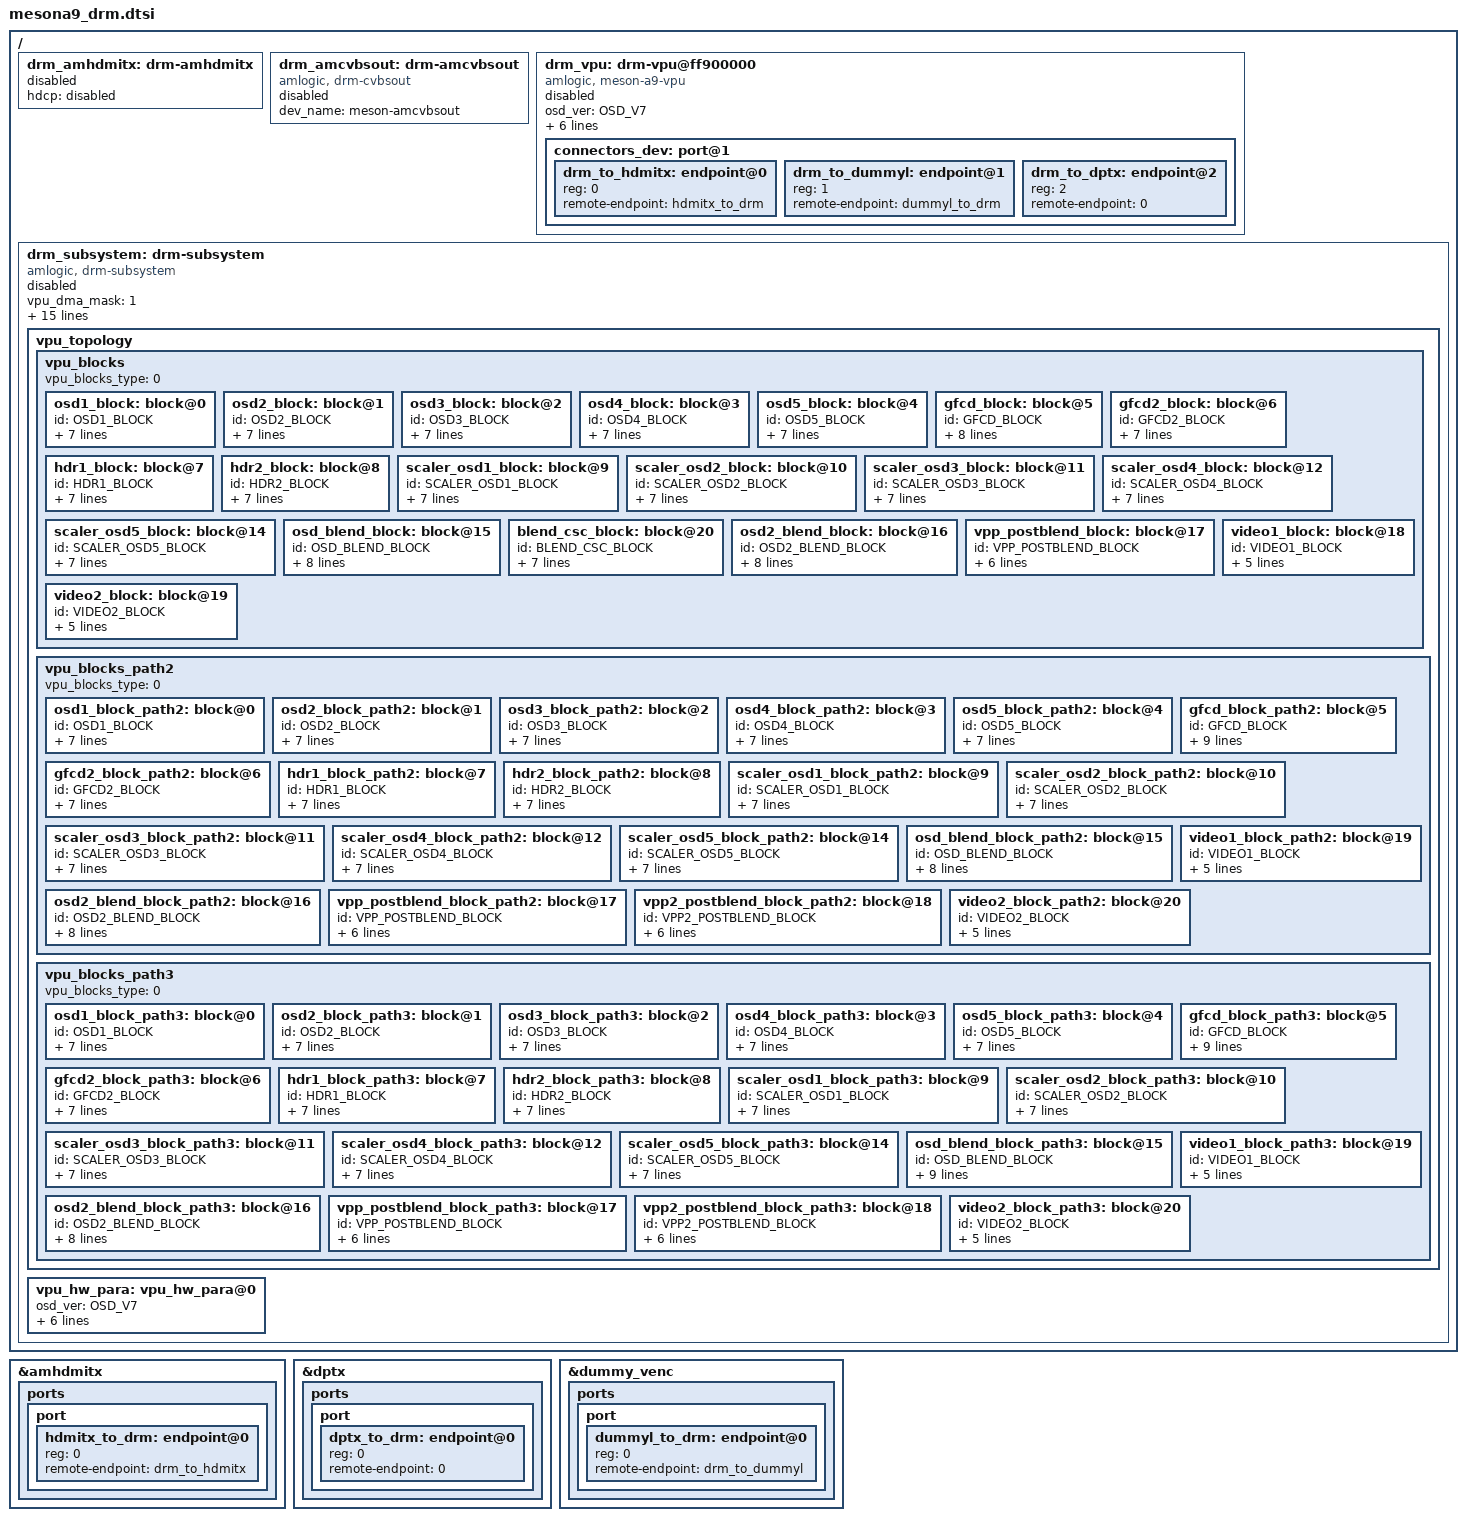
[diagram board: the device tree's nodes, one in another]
// SPDX-License-Identifier: (GPL-2.0+ OR MIT)
/*
 * Copyright (c) 2019 Amlogic, Inc. All rights reserved.
 */

#include <dt-bindings/display/meson-drm-ids.h>
#include "meson-a9.dtsi"

/ {
	drm_amhdmitx: drm-amhdmitx {
		status = "disabled";
		hdcp = "disabled";
	};

	drm_amcvbsout: drm-amcvbsout {
		status = "disabled";
		compatible = "amlogic, drm-cvbsout";
		dev_name = "meson-amcvbsout";
		//ports {
		//	port {
		//		#address-cells = <1>;
		//		#size-cells = <0>;
		//	};
		//};
	};

	drm_vpu: drm-vpu@ff900000  {
		status = "disabled";
		//compatible = "amlogic, meson-s6-vpu";
		compatible = "amlogic, meson-a9-vpu";
		osd_ver = /bits/ 8 <OSD_V7>;
		reg = <0x0 0xff900000 0x0 0x40000>,
			  <0x0 0xff63c000 0x0 0x2000>,
			  <0x0 0xff638000 0x0 0x2000>;
		reg-names = "base", "hhi", "dmc";
		interrupts = <GIC_SPI 197 IRQ_TYPE_EDGE_RISING>,
				<GIC_SPI 194 IRQ_TYPE_EDGE_RISING>;
		interrupt-names = "viu-vsync", "viu2-vsync";
		dma-coherent;
		//clocks = <&clkc CLKID_VPU_CLKC>;
		//clock-names = "vpu_clkc";
		//assigned-clocks = <&clkc CLKID_VPU_CLKC>;
		//assigned-clock-rates = <200000000>;
		/*EXTERNAL port for driver outside of drm.*/
		connectors_dev: port@1 {
			#address-cells = <1>;
			#size-cells = <0>;
			drm_to_hdmitx: endpoint@0 {
				reg = <0>;
				remote-endpoint = <&hdmitx_to_drm>;
			};
			drm_to_dummyl: endpoint@1 {
				reg = <1>;
				remote-endpoint = <&dummyl_to_drm>;
			};
			drm_to_dptx: endpoint@2 {
				reg = <2>;
				remote-endpoint = <0>;
			};
			//drm_to_edp: endpoint@2 {
			//	reg = <1>;
			//	remote-endpoint = <&edp_to_drm>;
			//};
			//drm_to_dummyl: endpoint@1 {
			//	reg = <1>;
			//	remote-endpoint = <0>;
			//};
		};
	};

	drm_subsystem: drm-subsystem {
		status = "disabled";
		compatible = "amlogic, drm-subsystem";
		vpu_dma_mask = <1>; /* 0: <= 4G, 1: > 4G */
		ports = <&connectors_dev>;
		fbdev_sizes = <1920 1080 1920 2160 32>;
		max_fb_size = <1>; /** 0:1080p fb 1:4k fb */
		memory-region = <&logo_reserved>;
		primary_plane_index = <0>; /* primary plane index for crtcs */
		crtc_masks = <1 0 0>; /*for encoder: 0:hdmi 1:lcd 2:cvbs*/
		crtcmask_of_osd = <0 0 0 0 0>; /* indicate the crtc mask of osd plane */
		crtcmask_of_video = <0 1 0>; /* indicate the crtc mask of video plane */
		gamma_ctl = <0>; /*0:skip gamma init 1:gamma init*/
		pxp_mode = <0>;
		osd_afbc_mask = <7>;
		gfcd_enable = /bits/ 8  <1>;
		afbc_aligned_size = <1>; /*0:fbdev alloc non-afbc memory 1:fbdev alloc afbc memory*/
		vpu_block_select = <&vpu_blocks>; /*default vpu_blocks*/
		//vpu_block_select = <&vpu_blocks_path2>;
		//vpu_block_select = <&vpu_blocks_path3>;
		tx_venc = <&tx_venc>;

		vpu_topology: vpu_topology {
			vpu_blocks: vpu_blocks {
				/*0:scaler before osdblend, 1:hdr before osdblend*/
				vpu_blocks_type = <0>;
				osd1_block: block@0 {
					id = /bits/ 8 <OSD1_BLOCK>;
					index = /bits/ 8  <0>;
					type = /bits/ 8  <0>;
					block_name = "osd1_block";
					num_in_links = /bits/ 8  <0x0>;
					num_out_links = /bits/ 8  <0x1>;
					out_links = <0 &gfcd_block>;
					capability = /bits/ 64 <0x80000C9F>;
				};
				osd2_block: block@1 {
					id = /bits/ 8  <OSD2_BLOCK>;
					index = /bits/ 8  <1>;
					type = /bits/ 8  <0>;
					block_name = "osd2_block";
					num_in_links = /bits/ 8  <0x0>;
					num_out_links = /bits/ 8  <0x1>;
					out_links = <1 &gfcd_block>;
					capability = /bits/ 64 <0x80000C9F>;
				};
				osd3_block: block@2 {
					id = /bits/ 8  <OSD3_BLOCK>;
					index = /bits/ 8  <2>;
					type = /bits/ 8  <0>;
					block_name = "osd3_block";
					num_in_links = /bits/ 8  <0x0>;
					num_out_links = /bits/ 8  <0x1>;
					out_links = <0 &gfcd2_block>;
					capability = /bits/ 64 <0x80000C0F>;
				};
				osd4_block: block@3 {
					id = /bits/ 8  <OSD4_BLOCK>;
					index = /bits/ 8  <3>;
					type = /bits/ 8  <0>;
					block_name = "osd4_block";
					num_in_links = /bits/ 8  <0x0>;
					num_out_links = /bits/ 8  <0x1>;
					out_links = <0 &scaler_osd4_block>;
					capability = /bits/ 64 <0x80000C8E>;
				};
				osd5_block: block@4 {
					id = /bits/ 8  <OSD5_BLOCK>;
					index = /bits/ 8  <4>;
					type = /bits/ 8  <0>;
					block_name = "osd5_block";
					num_in_links = /bits/ 8  <0x0>;
					num_out_links = /bits/ 8  <0x1>;
					out_links = <0 &scaler_osd5_block>;
					capability = /bits/ 64 <0x80000C0E>;
				};
				gfcd_block: block@5 {
					id = /bits/ 8  <GFCD_BLOCK>;
					index = /bits/ 8  <0>;
					type = /bits/ 8  <9>;
					block_name = "gfcd_block";
					num_in_links = /bits/ 8  <0x2>;
					in_links = <0 &osd1_block>,
						<0 &osd2_block>;
					num_out_links = /bits/ 8  <0x2>;
					out_links = <0 &scaler_osd1_block>,
						<0 &scaler_osd2_block>;
				};
				gfcd2_block: block@6 {
					id = /bits/ 8  <GFCD2_BLOCK>;
					index = /bits/ 8  <1>;
					type = /bits/ 8  <9>;
					block_name = "gfcd2_block";
					num_in_links = /bits/ 8  <0x1>;
					in_links = <0 &osd3_block>;
					num_out_links = /bits/ 8  <0x1>;
					out_links = <0 &scaler_osd3_block>;
				};

				hdr1_block: block@7 {
					id = /bits/ 8  <HDR1_BLOCK>;
					index = /bits/ 8  <0>;
					block_name = "hdr1_block";
					type = /bits/ 8  <4>;
					num_in_links = /bits/ 8  <0x1>;
					in_links = <0 &scaler_osd1_block>;
					num_out_links = /bits/ 8  <0x1>;
					out_links = <0 &osd_blend_block>;
				};
				hdr2_block: block@8 {
					id = /bits/ 8  <HDR2_BLOCK>;
					index = /bits/ 8  <1>;
					block_name = "hdr2_block";
					type = /bits/ 8  <4>;
					num_in_links = /bits/ 8  <0x1>;
					in_links = <0 &scaler_osd2_block>;
					num_out_links = /bits/ 8  <0x1>;
					out_links = <1 &osd_blend_block>;
				};
				scaler_osd1_block: block@9 {
					id = /bits/ 8  <SCALER_OSD1_BLOCK>;
					index = /bits/ 8  <0>;
					type = /bits/ 8  <2>;
					block_name = "scaler_osd1_block";
					num_in_links = /bits/ 8  <0x1>;
					in_links = <0 &gfcd_block>;
					num_out_links = /bits/ 8  <0x1>;
					out_links = <0 &hdr1_block>;
				};
				scaler_osd2_block: block@10 {
					id = /bits/ 8  <SCALER_OSD2_BLOCK>;
					index = /bits/ 8  <1>;
					type = /bits/ 8  <2>;
					block_name = "scaler_osd2_block";
					num_in_links = /bits/ 8  <0x1>;
					in_links = <1 &gfcd_block>;
					num_out_links = /bits/ 8  <0x1>;
					out_links = <0 &hdr2_block>;
				};
				scaler_osd3_block: block@11 {
					id = /bits/ 8  <SCALER_OSD3_BLOCK>;
					index = /bits/ 8  <2>;
					type = /bits/ 8  <2>;
					block_name = "scaler_osd3_block";
					num_in_links = /bits/ 8  <0x1>;
					in_links = <0 &gfcd2_block>;
					num_out_links = /bits/ 8  <0x1>;
					out_links = <2 &osd_blend_block>;
				};
				scaler_osd4_block: block@12 {
					id = /bits/ 8  <SCALER_OSD4_BLOCK>;
					index = /bits/ 8  <3>;
					type = /bits/ 8  <2>;
					block_name = "scaler_osd4_block";
					num_in_links = /bits/ 8  <0x1>;
					in_links = <0 &osd4_block>;
					num_out_links = /bits/ 8  <0x1>;
					out_links = <0 &osd2_blend_block>;
				};
				scaler_osd5_block: block@14 {
					id = /bits/ 8  <SCALER_OSD5_BLOCK>;
					index = /bits/ 8  <4>;
					type = /bits/ 8  <2>;
					block_name = "scaler_osd5_block";
					num_in_links = /bits/ 8  <0x1>;
					in_links = <0 &osd5_block>;
					num_out_links = /bits/ 8  <0x1>;
					out_links = <1 &osd2_blend_block>;
				};
				osd_blend_block: block@15 {
					id = /bits/ 8  <OSD_BLEND_BLOCK>;
					index = /bits/ 8  <0>;
					block_name = "osd_blend_block";
					type = /bits/ 8  <3>;
					num_in_links = /bits/ 8  <0x4>;
					in_links = <0 &hdr1_block>,
						<0 &hdr2_block>,
						<0 &scaler_osd3_block>,
						<0 &osd2_blend_block>;
					num_out_links = /bits/ 8  <0x1>;
					out_links = <0 &blend_csc_block>;
				};
				blend_csc_block: block@20 {
					id = /bits/ 8  <BLEND_CSC_BLOCK>;
					index = /bits/ 8  <0>;
					block_name = "blend_csc_block";
					type = /bits/ 8  <10>;
					num_in_links = /bits/ 8  <0x1>;
					in_links = <0 &osd_blend_block>;
					num_out_links = /bits/ 8  <0x1>;
					out_links = <0 &vpp_postblend_block>;
				};
				osd2_blend_block: block@16 {
					id = /bits/ 8  <OSD2_BLEND_BLOCK>;
					index = /bits/ 8  <1>;
					block_name = "osd2_blend_block";
					type = /bits/ 8  <3>;
					num_in_links = /bits/ 8  <0x2>;
					in_links = <0 &scaler_osd4_block>,
						<0 &scaler_osd5_block>;
					num_out_links = /bits/ 8  <0x1>;
					out_links = <3 &osd_blend_block>;
				};
				vpp_postblend_block: block@17 {
					id = /bits/ 8  <VPP_POSTBLEND_BLOCK>;
					index = /bits/ 8  <0>;
					block_name = "vpp_postblend_block";
					type = /bits/ 8  <6>;
					num_in_links = /bits/ 8  <0x1>;
					in_links = <0 &blend_csc_block>;
					num_out_links = <0x0>;
				};
				//vpp2_postblend_block: block@18 {
				//	id = /bits/ 8  <VPP2_POSTBLEND_BLOCK>;
				//	index = /bits/ 8  <1>;
				//	block_name = "vpp2_postblend_block";
				//	type = /bits/ 8  <6>;
				//	num_in_links = /bits/ 8  <0x0>;
					//in_links = <0x0>;
					//num_out_links = <0x0>;
				//};
				video1_block: block@18 {
					id = /bits/ 8 <VIDEO1_BLOCK>;
					index = /bits/ 8  <0>;
					type = /bits/ 8  <7>;
					block_name = "video1_block";
					num_in_links = /bits/ 8  <0x0>;
					num_out_links = /bits/ 8  <0x0>;
				};
				video2_block: block@19 {
					id = /bits/ 8 <VIDEO2_BLOCK>;
					index = /bits/ 8  <1>;
					type = /bits/ 8  <7>;
					block_name = "video2_block";
					num_in_links = /bits/ 8  <0x0>;
					num_out_links = /bits/ 8  <0x0>;
				};
			};

			vpu_blocks_path2: vpu_blocks_path2 {
				/*osd3->vpp2*/
				vpu_blocks_type = <0>;
				osd1_block_path2: block@0 {
					id = /bits/ 8 <OSD1_BLOCK>;
					index = /bits/ 8  <0>;
					type = /bits/ 8  <0>;
					block_name = "osd1_block";
					num_in_links = /bits/ 8  <0x0>;
					num_out_links = /bits/ 8  <0x1>;
					out_links = <0 &gfcd_block_path2>;
					capability = /bits/ 64 <0x80000C9F>;
				};
				osd2_block_path2: block@1 {
					id = /bits/ 8  <OSD2_BLOCK>;
					index = /bits/ 8  <1>;
					type = /bits/ 8  <0>;
					block_name = "osd2_block";
					num_in_links = /bits/ 8  <0x0>;
					num_out_links = /bits/ 8  <0x1>;
					out_links = <1 &gfcd_block_path2>;
					capability = /bits/ 64 <0x80000C9F>;
				};
				osd3_block_path2: block@2 {
					id = /bits/ 8  <OSD3_BLOCK>;
					index = /bits/ 8  <2>;
					type = /bits/ 8  <0>;
					block_name = "osd3_block";
					num_in_links = /bits/ 8  <0x0>;
					num_out_links = /bits/ 8  <0x1>;
					out_links = <0 &gfcd2_block_path2>;
					capability = /bits/ 64 <0x8000040F>;
				};
				osd4_block_path2: block@3 {
					id = /bits/ 8  <OSD4_BLOCK>;
					index = /bits/ 8  <3>;
					type = /bits/ 8  <0>;
					block_name = "osd4_block";
					num_in_links = /bits/ 8  <0x0>;
					num_out_links = /bits/ 8  <0x1>;
					out_links = <0 &scaler_osd4_block_path2>;
					capability = /bits/ 64 <0x80000C8E>;
				};
				osd5_block_path2: block@4 {
					id = /bits/ 8  <OSD5_BLOCK>;
					index = /bits/ 8  <4>;
					type = /bits/ 8  <0>;
					block_name = "osd5_block";
					num_in_links = /bits/ 8  <0x0>;
					num_out_links = /bits/ 8  <0x1>;
					out_links = <0 &scaler_osd5_block_path2>;
					capability = /bits/ 64 <0x80000C0E>;
				};
				gfcd_block_path2: block@5 {
					id = /bits/ 8  <GFCD_BLOCK>;
					index = /bits/ 8  <0>;
					type = /bits/ 8  <9>;
					block_name = "gfcd_block";
					num_in_links = /bits/ 8  <0x2>;
					in_links = <0 &osd1_block_path2>,
						<0 &osd2_block_path2>;
					num_out_links = /bits/ 8  <0x2>;
					out_links = <0 &scaler_osd1_block_path2>,
						<0 &scaler_osd2_block_path2>;
				};
				gfcd2_block_path2: block@6 {
					id = /bits/ 8  <GFCD2_BLOCK>;
					index = /bits/ 8  <1>;
					type = /bits/ 8  <9>;
					block_name = "gfcd2_block";
					num_in_links = /bits/ 8  <0x1>;
					in_links = <0 &osd3_block_path2>;
					num_out_links = /bits/ 8  <0x1>;
					out_links = <0 &scaler_osd3_block_path2>;
				};

				hdr1_block_path2: block@7 {
					id = /bits/ 8  <HDR1_BLOCK>;
					index = /bits/ 8  <0>;
					block_name = "hdr1_block";
					type = /bits/ 8  <4>;
					num_in_links = /bits/ 8  <0x1>;
					in_links = <0 &scaler_osd1_block_path2>;
					num_out_links = /bits/ 8  <0x1>;
					out_links = <0 &osd_blend_block_path2>;
				};
				hdr2_block_path2: block@8 {
					id = /bits/ 8  <HDR2_BLOCK>;
					index = /bits/ 8  <1>;
					block_name = "hdr2_block";
					type = /bits/ 8  <4>;
					num_in_links = /bits/ 8  <0x1>;
					in_links = <0 &scaler_osd2_block_path2>;
					num_out_links = /bits/ 8  <0x1>;
					out_links = <1 &osd_blend_block_path2>;
				};
				scaler_osd1_block_path2: block@9 {
					id = /bits/ 8  <SCALER_OSD1_BLOCK>;
					index = /bits/ 8  <0>;
					type = /bits/ 8  <2>;
					block_name = "scaler_osd1_block";
					num_in_links = /bits/ 8  <0x1>;
					in_links = <0 &gfcd_block_path2>;
					num_out_links = /bits/ 8  <0x1>;
					out_links = <0 &hdr1_block_path2>;
				};
				scaler_osd2_block_path2: block@10 {
					id = /bits/ 8  <SCALER_OSD2_BLOCK>;
					index = /bits/ 8  <1>;
					type = /bits/ 8  <2>;
					block_name = "scaler_osd2_block";
					num_in_links = /bits/ 8  <0x1>;
					in_links = <1 &gfcd_block_path2>;
					num_out_links = /bits/ 8  <0x1>;
					out_links = <0 &hdr2_block_path2>;
				};
				scaler_osd3_block_path2: block@11 {
					id = /bits/ 8  <SCALER_OSD3_BLOCK>;
					index = /bits/ 8  <2>;
					type = /bits/ 8  <2>;
					block_name = "scaler_osd3_block";
					num_in_links = /bits/ 8  <0x1>;
					in_links = <0 &gfcd2_block_path2>;
					num_out_links = /bits/ 8  <0x1>;
					out_links = <0 &vpp2_postblend_block_path2>;
				};
				scaler_osd4_block_path2: block@12 {
					id = /bits/ 8  <SCALER_OSD4_BLOCK>;
					index = /bits/ 8  <3>;
					type = /bits/ 8  <2>;
					block_name = "scaler_osd4_block";
					num_in_links = /bits/ 8  <0x1>;
					in_links = <0 &osd4_block_path2>;
					num_out_links = /bits/ 8  <0x1>;
					out_links = <0 &osd2_blend_block_path2>;
				};
				scaler_osd5_block_path2: block@14 {
					id = /bits/ 8  <SCALER_OSD5_BLOCK>;
					index = /bits/ 8  <4>;
					type = /bits/ 8  <2>;
					block_name = "scaler_osd5_block";
					num_in_links = /bits/ 8  <0x1>;
					in_links = <0 &osd5_block_path2>;
					num_out_links = /bits/ 8  <0x1>;
					out_links = <1 &osd2_blend_block_path2>;
				};
				osd_blend_block_path2: block@15 {
					id = /bits/ 8  <OSD_BLEND_BLOCK>;
					index = /bits/ 8  <0>;
					block_name = "osd_blend_block";
					type = /bits/ 8  <3>;
					num_in_links = /bits/ 8  <0x3>;
					in_links = <0 &hdr1_block_path2>,
						<0 &hdr2_block_path2>,
						<0 &osd2_blend_block_path2>;
					num_out_links = /bits/ 8  <0x1>;
					out_links = <0 &vpp_postblend_block_path2>;
				};
				osd2_blend_block_path2: block@16 {
					id = /bits/ 8  <OSD2_BLEND_BLOCK>;
					index = /bits/ 8  <1>;
					block_name = "osd2_blend_block";
					type = /bits/ 8  <3>;
					num_in_links = /bits/ 8  <0x2>;
					in_links = <0 &scaler_osd4_block_path2>,
						<0 &scaler_osd5_block_path2>;
					num_out_links = /bits/ 8  <0x1>;
					out_links = <2 &osd_blend_block_path2>;
				};
				vpp_postblend_block_path2: block@17 {
					id = /bits/ 8  <VPP_POSTBLEND_BLOCK>;
					index = /bits/ 8  <0>;
					block_name = "vpp_postblend_block";
					type = /bits/ 8  <6>;
					num_in_links = /bits/ 8  <0x1>;
					in_links = <0 &osd_blend_block_path2>;
					num_out_links = <0x0>;
				};
				vpp2_postblend_block_path2: block@18 {
					id = /bits/ 8  <VPP2_POSTBLEND_BLOCK>;
					index = /bits/ 8  <1>;
					block_name = "vpp2_postblend_block";
					type = /bits/ 8  <6>;
					num_in_links = /bits/ 8  <0x1>;
					in_links = <0 &scaler_osd3_block_path2>;
					num_out_links = <0x0>;
				};
				video1_block_path2: block@19 {
					id = /bits/ 8 <VIDEO1_BLOCK>;
					index = /bits/ 8  <0>;
					type = /bits/ 8  <7>;
					block_name = "video1_block";
					num_in_links = /bits/ 8  <0x0>;
					num_out_links = /bits/ 8  <0x0>;
				};
				video2_block_path2: block@20 {
					id = /bits/ 8 <VIDEO2_BLOCK>;
					index = /bits/ 8  <1>;
					type = /bits/ 8  <7>;
					block_name = "video2_block";
					num_in_links = /bits/ 8  <0x0>;
					num_out_links = /bits/ 8  <0x0>;
				};
			};

			vpu_blocks_path3: vpu_blocks_path3 {
				/*osd2 -> vpp2*/
				vpu_blocks_type = <0>;
				osd1_block_path3: block@0 {
					id = /bits/ 8 <OSD1_BLOCK>;
					index = /bits/ 8  <0>;
					type = /bits/ 8  <0>;
					block_name = "osd1_block";
					num_in_links = /bits/ 8  <0x0>;
					num_out_links = /bits/ 8  <0x1>;
					out_links = <0 &gfcd_block_path3>;
					capability = /bits/ 64 <0x80000C9F>;
				};
				osd2_block_path3: block@1 {
					id = /bits/ 8  <OSD2_BLOCK>;
					index = /bits/ 8  <1>;
					type = /bits/ 8  <0>;
					block_name = "osd2_block";
					num_in_links = /bits/ 8  <0x0>;
					num_out_links = /bits/ 8  <0x1>;
					out_links = <1 &gfcd_block_path3>;
					capability = /bits/ 64 <0x8000049F>;
				};
				osd3_block_path3: block@2 {
					id = /bits/ 8  <OSD3_BLOCK>;
					index = /bits/ 8  <2>;
					type = /bits/ 8  <0>;
					block_name = "osd3_block";
					num_in_links = /bits/ 8  <0x0>;
					num_out_links = /bits/ 8  <0x1>;
					out_links = <0 &gfcd2_block_path3>;
					capability = /bits/ 64 <0x80000C0F>;
				};
				osd4_block_path3: block@3 {
					id = /bits/ 8  <OSD4_BLOCK>;
					index = /bits/ 8  <3>;
					type = /bits/ 8  <0>;
					block_name = "osd4_block";
					num_in_links = /bits/ 8  <0x0>;
					num_out_links = /bits/ 8  <0x1>;
					out_links = <0 &scaler_osd4_block_path3>;
					capability = /bits/ 64 <0x80000C8E>;
				};
				osd5_block_path3: block@4 {
					id = /bits/ 8  <OSD5_BLOCK>;
					index = /bits/ 8  <4>;
					type = /bits/ 8  <0>;
					block_name = "osd5_block";
					num_in_links = /bits/ 8  <0x0>;
					num_out_links = /bits/ 8  <0x1>;
					out_links = <0 &scaler_osd5_block_path3>;
					capability = /bits/ 64 <0x80000C0E>;
				};
				gfcd_block_path3: block@5 {
					id = /bits/ 8  <GFCD_BLOCK>;
					index = /bits/ 8  <0>;
					type = /bits/ 8  <9>;
					block_name = "gfcd_block";
					num_in_links = /bits/ 8  <0x2>;
					in_links = <0 &osd1_block_path3>,
						<0 &osd2_block_path3>;
					num_out_links = /bits/ 8  <0x2>;
					out_links = <0 &scaler_osd1_block_path3>,
						<0 &scaler_osd2_block_path3>;
				};
				gfcd2_block_path3: block@6 {
					id = /bits/ 8  <GFCD2_BLOCK>;
					index = /bits/ 8  <1>;
					type = /bits/ 8  <9>;
					block_name = "gfcd2_block";
					num_in_links = /bits/ 8  <0x1>;
					in_links = <0 &osd3_block_path3>;
					num_out_links = /bits/ 8  <0x1>;
					out_links = <0 &scaler_osd3_block_path3>;
				};

				hdr1_block_path3: block@7 {
					id = /bits/ 8  <HDR1_BLOCK>;
					index = /bits/ 8  <0>;
					block_name = "hdr1_block";
					type = /bits/ 8  <4>;
					num_in_links = /bits/ 8  <0x1>;
					in_links = <0 &scaler_osd1_block_path3>;
					num_out_links = /bits/ 8  <0x1>;
					out_links = <0 &osd_blend_block_path3>;
				};
				hdr2_block_path3: block@8 {
					id = /bits/ 8  <HDR2_BLOCK>;
					index = /bits/ 8  <1>;
					block_name = "hdr2_block";
					type = /bits/ 8  <4>;
					num_in_links = /bits/ 8  <0x1>;
					in_links = <0 &scaler_osd2_block_path3>;
					num_out_links = /bits/ 8  <0x1>;
					out_links = <0 &vpp2_postblend_block_path3>;
				};
				scaler_osd1_block_path3: block@9 {
					id = /bits/ 8  <SCALER_OSD1_BLOCK>;
					index = /bits/ 8  <0>;
					type = /bits/ 8  <2>;
					block_name = "scaler_osd1_block";
					num_in_links = /bits/ 8  <0x1>;
					in_links = <0 &gfcd_block_path3>;
					num_out_links = /bits/ 8  <0x1>;
					out_links = <0 &hdr1_block_path3>;
				};
				scaler_osd2_block_path3: block@10 {
					id = /bits/ 8  <SCALER_OSD2_BLOCK>;
					index = /bits/ 8  <1>;
					type = /bits/ 8  <2>;
					block_name = "scaler_osd2_block";
					num_in_links = /bits/ 8  <0x1>;
					in_links = <1 &gfcd_block_path3>;
					num_out_links = /bits/ 8  <0x1>;
					out_links = <0 &hdr2_block_path3>;
				};
				scaler_osd3_block_path3: block@11 {
					id = /bits/ 8  <SCALER_OSD3_BLOCK>;
					index = /bits/ 8  <2>;
					type = /bits/ 8  <2>;
					block_name = "scaler_osd3_block";
					num_in_links = /bits/ 8  <0x1>;
					in_links = <0 &gfcd2_block_path3>;
					num_out_links = /bits/ 8  <0x1>;
					out_links = <1 &osd_blend_block_path3>;
				};
				scaler_osd4_block_path3: block@12 {
					id = /bits/ 8  <SCALER_OSD4_BLOCK>;
					index = /bits/ 8  <3>;
					type = /bits/ 8  <2>;
					block_name = "scaler_osd4_block";
					num_in_links = /bits/ 8  <0x1>;
					in_links = <0 &osd4_block_path3>;
					num_out_links = /bits/ 8  <0x1>;
					out_links = <0 &osd2_blend_block_path3>;
				};
				scaler_osd5_block_path3: block@14 {
					id = /bits/ 8  <SCALER_OSD5_BLOCK>;
					index = /bits/ 8  <4>;
					type = /bits/ 8  <2>;
					block_name = "scaler_osd5_block";
					num_in_links = /bits/ 8  <0x1>;
					in_links = <0 &osd5_block_path3>;
					num_out_links = /bits/ 8  <0x1>;
					out_links = <1 &osd2_blend_block_path3>;
				};
				osd_blend_block_path3: block@15 {
					id = /bits/ 8  <OSD_BLEND_BLOCK>;
					index = /bits/ 8  <0>;
					block_name = "osd_blend_block";
					type = /bits/ 8  <3>;
					num_in_links = /bits/ 8  <0x3>;
					in_links = <0 &hdr1_block_path3>,
						<0 &scaler_osd3_block_path3>,
						<0 &osd2_blend_block_path3>;
					num_out_links = /bits/ 8  <0x1>;
					out_links = <0 &vpp_postblend_block_path3>;
				};
				osd2_blend_block_path3: block@16 {
					id = /bits/ 8  <OSD2_BLEND_BLOCK>;
					index = /bits/ 8  <1>;
					block_name = "osd2_blend_block";
					type = /bits/ 8  <3>;
					num_in_links = /bits/ 8  <0x2>;
					in_links = <0 &scaler_osd4_block_path3>,
						<0 &scaler_osd5_block_path3>;
					num_out_links = /bits/ 8  <0x1>;
					out_links = <2 &osd_blend_block_path3>;
				};
				vpp_postblend_block_path3: block@17 {
					id = /bits/ 8  <VPP_POSTBLEND_BLOCK>;
					index = /bits/ 8  <0>;
					block_name = "vpp_postblend_block";
					type = /bits/ 8  <6>;
					num_in_links = /bits/ 8  <0x1>;
					in_links = <0 &osd_blend_block_path3>;
					num_out_links = <0x0>;
				};
				vpp2_postblend_block_path3: block@18 {
					id = /bits/ 8  <VPP2_POSTBLEND_BLOCK>;
					index = /bits/ 8  <1>;
					block_name = "vpp2_postblend_block";
					type = /bits/ 8  <6>;
					num_in_links = /bits/ 8  <0x1>;
					in_links = <0 &hdr2_block_path3>;
					num_out_links = <0x0>;
				};
				video1_block_path3: block@19 {
					id = /bits/ 8 <VIDEO1_BLOCK>;
					index = /bits/ 8  <0>;
					type = /bits/ 8  <7>;
					block_name = "video1_block";
					num_in_links = /bits/ 8  <0x0>;
					num_out_links = /bits/ 8  <0x0>;
				};
				video2_block_path3: block@20 {
					id = /bits/ 8 <VIDEO2_BLOCK>;
					index = /bits/ 8  <1>;
					type = /bits/ 8  <7>;
					block_name = "video2_block";
					num_in_links = /bits/ 8  <0x0>;
					num_out_links = /bits/ 8  <0x0>;
				};
			};
		};
		vpu_hw_para: vpu_hw_para@0 {
			osd_ver = /bits/ 8 <OSD_V7>;
			afbc_type = /bits/ 8 <0x2>;
			has_deband = /bits/ 8 <0x1>;
			has_lut = /bits/ 8 <0x1>;
			has_rdma = /bits/ 8 <0x1>;
			osd_fifo_len = /bits/ 8 <64>;
			vpp_fifo_len = /bits/ 32 <0xfff>;
		};
	};
};

&amhdmitx {
	ports {
		port {
			#address-cells = <1>;
			#size-cells = <0>;
			hdmitx_to_drm: endpoint@0 {
				reg = <0>;
				remote-endpoint = <&drm_to_hdmitx>;
			};
		};
	};
};

&dptx {
	ports {
		port {
			#address-cells = <1>;
			#size-cells = <0>;
			dptx_to_drm: endpoint@0 {
				reg = <0>;
				remote-endpoint = <0>;
			};
		};
	};
};

//&edptx {
//	ports {
//		port {
//			#address-cells = <1>;
//			#size-cells = <0>;
//			edp_to_drm: endpoint@0 {
//				reg = <0>;
//				remote-endpoint = <&drm_to_edp>;
//			};
//		};
//	};
//};

&dummy_venc {
	ports {
		port {
			#address-cells = <1>;
			#size-cells = <0>;
			dummyl_to_drm: endpoint@0 {
				reg = <0>;
				remote-endpoint = <&drm_to_dummyl>;
			};
		};
	};
};
